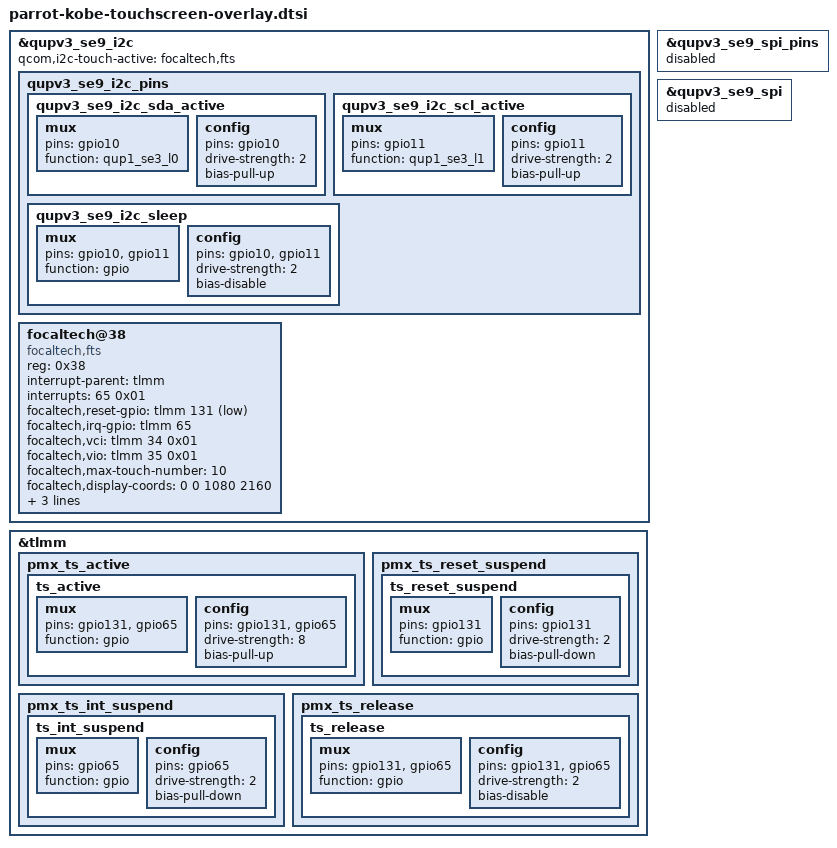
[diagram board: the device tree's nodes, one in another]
&qupv3_se9_i2c {
        qupv3_se9_i2c_pins: qupv3_se9_i2c_pins {
		qupv3_se9_i2c_sda_active: qupv3_se9_i2c_sda_active {
			mux {
				pins = "gpio10";
				function = "qup1_se3_l0";
			};

			config {
				pins = "gpio10";
				drive-strength = <2>;
				bias-pull-up;
			};
		};

		qupv3_se9_i2c_scl_active: qupv3_se9_i2c_scl_active {
			mux {
				pins = "gpio11";
				function = "qup1_se3_l1";
			};

			config {
				pins = "gpio11";
				drive-strength = <2>;
				bias-pull-up;
			};
		};

		qupv3_se9_i2c_sleep: qupv3_se9_i2c_sleep {
			mux {
				pins = "gpio10", "gpio11";
				function = "gpio";
			};

			config {
				pins = "gpio10", "gpio11";
				drive-strength = <2>;
				bias-disable;
			};
		};
	};
};

&qupv3_se9_spi_pins {
	status = "disabled";
};


&tlmm{
	pmx_ts_active {
			ts_active: ts_active {
				mux {
					pins = "gpio131", "gpio65";
					function = "gpio";
				};

				config {
					pins = "gpio131", "gpio65";
					drive-strength = <8>;
					bias-pull-up;
				};
			};
		};

		pmx_ts_reset_suspend {
			ts_reset_suspend: ts_reset_suspend {
				mux {
					pins = "gpio131";
					function = "gpio";
				};

				config {
					pins = "gpio131";
					drive-strength = <2>;
					bias-pull-down;
				};
			};
		};

		pmx_ts_int_suspend {
			ts_int_suspend: ts_int_suspend {
				mux {
					pins = "gpio65";
					function = "gpio";
				};

				config {
					pins = "gpio65";
					drive-strength = <2>;
					bias-pull-down;
				};
			};
		};

		pmx_ts_release {
			ts_release: ts_release {
				mux {
					pins = "gpio131", "gpio65";
					function = "gpio";
				};

				config {
					pins = "gpio131", "gpio65";
					drive-strength = <2>;
					bias-disable;
				};
			};
		};
};

&qupv3_se9_i2c {
    status = "okay";
    qcom,i2c-touch-active="focaltech,fts";
    focaltech@38{
        compatible = "focaltech,fts";
        reg = <0x38>;
        interrupt-parent = <&tlmm>;
        interrupts = <65 0x01>;
        focaltech,reset-gpio = <&tlmm 131 0x01>;
        focaltech,irq-gpio = <&tlmm 65 0x02>;
		focaltech,vci = <&tlmm 34 0x01>;
		focaltech,vio = <&tlmm 35 0x01>;
        focaltech,max-touch-number = <10>;
        focaltech,display-coords =  <0 0 1080 2160>;
	pinctrl-names = "pmx_ts_active","pmx_ts_suspend","pmx_ts_release";
        pinctrl-0 = <&ts_active>;
        pinctrl-1 = <&ts_int_suspend &ts_reset_suspend>;
        pinctrl-2 = <&ts_release>;
    };
};
&qupv3_se9_spi {
         status = "disabled";
};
